AUTOSAR XML (schema 4-2-2)
package /AUTOSAR_Dcm/SwComponentTypes
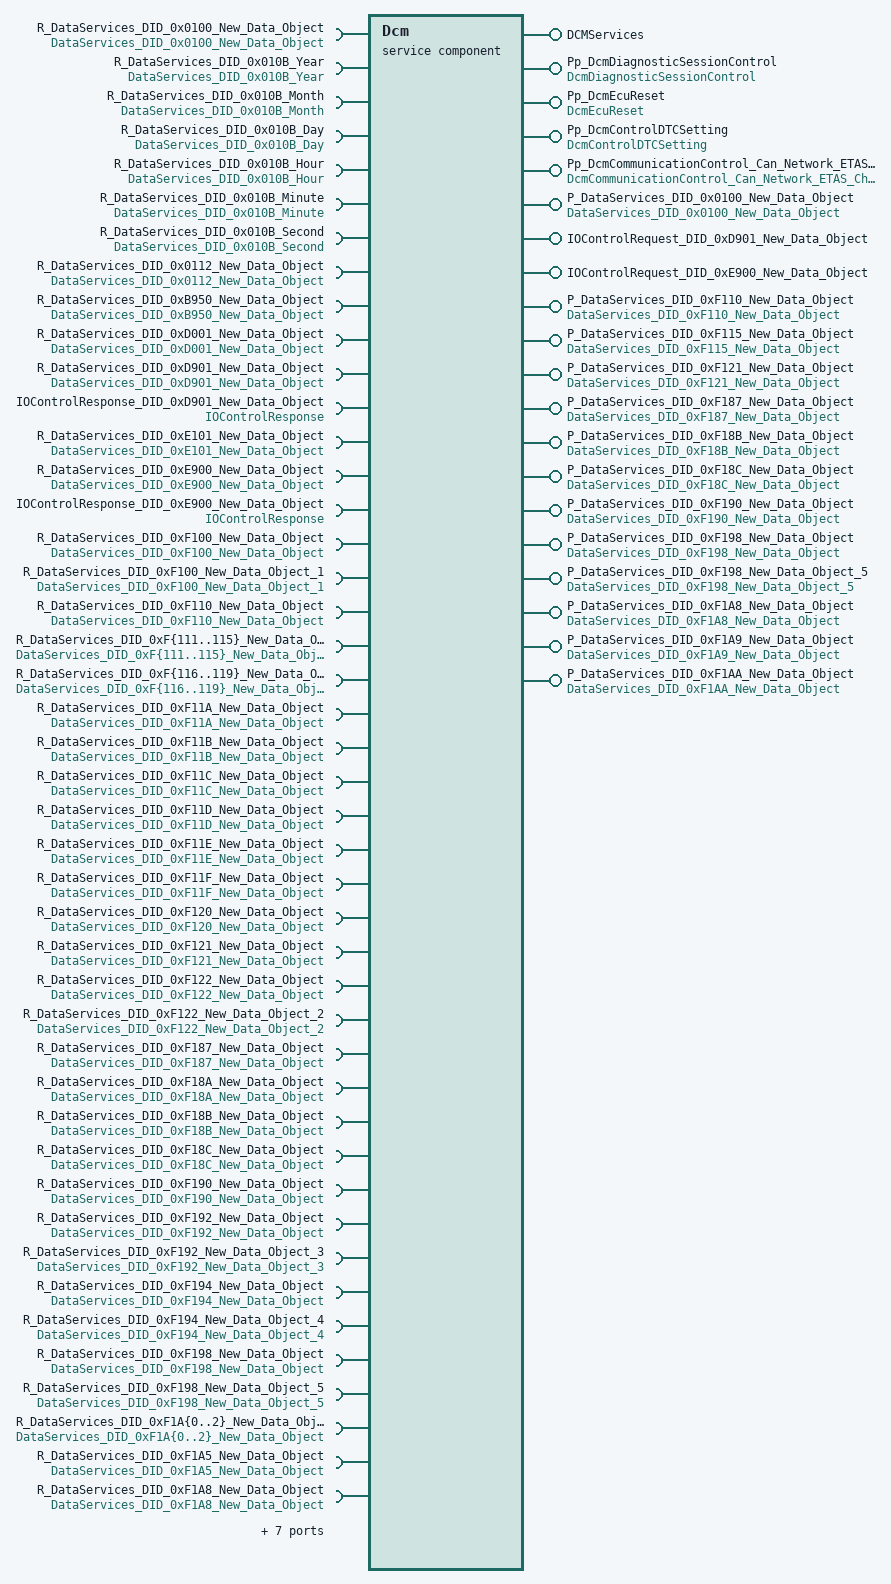
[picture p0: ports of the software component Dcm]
  service sw component type Dcm
    5 x provide port:
      DCMServices: provided-interface=DCMServices
        provided-com-specs:
          operation=GetActiveProtocol, queue-length=1
          operation=SetActiveDiagnostic, queue-length=1
          operation=GetSesCtrlType, queue-length=1
          operation=GetSecurityLevel, queue-length=1
          operation=ResetToDefaultSession, queue-length=1
      Pp_DcmDiagnosticSessionControl: mode-switch-sender-com-spec{mode-group=MDGP_DcmDiagnosticSessionControl, queue-length=1}, provided-interface=DcmDiagnosticSessionControl
      Pp_DcmEcuReset: mode-switch-sender-com-spec{mode-group=MDGP_DcmEcuReset, queue-length=1}, provided-interface=DcmEcuReset
      Pp_DcmControlDTCSetting: mode-switch-sender-com-spec{mode-group=MDGP_DcmControlDTCSetting, queue-length=1}, provided-interface=DcmControlDTCSetting
      Pp_DcmCommunicationControl_Can_Network_ETAS_Channel_Can_Network_ETAS: mode-switch-sender-com-spec{mode-group=MDGP_DcmCommunicationControl_Can_Network_ETAS_Channel_Can_Network_ETAS, queue-length=1}, provided-interface=DcmCommunicationControl_Can_Network_ETAS_Channel_Can_Network_ETAS
    require port R_DataServices_DID_0x0100_New_Data_Object: required-interface=DataServices_DID_0x0100_New_Data_Object
    provide port P_DataServices_DID_0x0100_New_Data_Object: provided-interface=DataServices_DID_0x0100_New_Data_Object
    10 x require port:
      R_DataServices_DID_0x010B_Year: required-interface=DataServices_DID_0x010B_Year
      R_DataServices_DID_0x010B_Month: required-interface=DataServices_DID_0x010B_Month
      R_DataServices_DID_0x010B_Day: required-interface=DataServices_DID_0x010B_Day
      R_DataServices_DID_0x010B_Hour: required-interface=DataServices_DID_0x010B_Hour
      R_DataServices_DID_0x010B_Minute: required-interface=DataServices_DID_0x010B_Minute
      R_DataServices_DID_0x010B_Second: required-interface=DataServices_DID_0x010B_Second
      R_DataServices_DID_0x0112_New_Data_Object: required-interface=DataServices_DID_0x0112_New_Data_Object
      R_DataServices_DID_0xB950_New_Data_Object: required-interface=DataServices_DID_0xB950_New_Data_Object
      R_DataServices_DID_0xD001_New_Data_Object: required-interface=DataServices_DID_0xD001_New_Data_Object
      R_DataServices_DID_0xD901_New_Data_Object: required-interface=DataServices_DID_0xD901_New_Data_Object
    provide port IOControlRequest_DID_0xD901_New_Data_Object: provided-interface=IOControlRequest_DID_0xD901_New_Data_Object
    require port IOControlResponse_DID_0xD901_New_Data_Object: required-interface=IOControlResponse
    require port R_DataServices_DID_0xE101_New_Data_Object: required-interface=DataServices_DID_0xE101_New_Data_Object
    require port R_DataServices_DID_0xE900_New_Data_Object: required-interface=DataServices_DID_0xE900_New_Data_Object
    provide port IOControlRequest_DID_0xE900_New_Data_Object: provided-interface=IOControlRequest_DID_0xE900_New_Data_Object
    4 x require port:
      IOControlResponse_DID_0xE900_New_Data_Object: required-interface=IOControlResponse
      R_DataServices_DID_0xF100_New_Data_Object: required-interface=DataServices_DID_0xF100_New_Data_Object
      R_DataServices_DID_0xF100_New_Data_Object_1: required-interface=DataServices_DID_0xF100_New_Data_Object_1
      R_DataServices_DID_0xF110_New_Data_Object: required-interface=DataServices_DID_0xF110_New_Data_Object
    provide port P_DataServices_DID_0xF110_New_Data_Object: provided-interface=DataServices_DID_0xF110_New_Data_Object
    5 x require port:
      R_DataServices_DID_0xF{111..115}_New_Data_Object: required-interface=DataServices_DID_0xF{111..115}_New_Data_Object
    provide port P_DataServices_DID_0xF115_New_Data_Object: provided-interface=DataServices_DID_0xF115_New_Data_Object
    12 x require port:
      R_DataServices_DID_0xF{116..119}_New_Data_Object: required-interface=DataServices_DID_0xF{116..119}_New_Data_Object
      R_DataServices_DID_0xF11A_New_Data_Object: required-interface=DataServices_DID_0xF11A_New_Data_Object
      R_DataServices_DID_0xF11B_New_Data_Object: required-interface=DataServices_DID_0xF11B_New_Data_Object
      R_DataServices_DID_0xF11C_New_Data_Object: required-interface=DataServices_DID_0xF11C_New_Data_Object
      R_DataServices_DID_0xF11D_New_Data_Object: required-interface=DataServices_DID_0xF11D_New_Data_Object
      R_DataServices_DID_0xF11E_New_Data_Object: required-interface=DataServices_DID_0xF11E_New_Data_Object
      R_DataServices_DID_0xF11F_New_Data_Object: required-interface=DataServices_DID_0xF11F_New_Data_Object
      R_DataServices_DID_0xF120_New_Data_Object: required-interface=DataServices_DID_0xF120_New_Data_Object
      R_DataServices_DID_0xF121_New_Data_Object: required-interface=DataServices_DID_0xF121_New_Data_Object
    provide port P_DataServices_DID_0xF121_New_Data_Object: provided-interface=DataServices_DID_0xF121_New_Data_Object
    require port R_DataServices_DID_0xF122_New_Data_Object: required-interface=DataServices_DID_0xF122_New_Data_Object
    require port R_DataServices_DID_0xF122_New_Data_Object_2: required-interface=DataServices_DID_0xF122_New_Data_Object_2
    require port R_DataServices_DID_0xF187_New_Data_Object: required-interface=DataServices_DID_0xF187_New_Data_Object
    provide port P_DataServices_DID_0xF187_New_Data_Object: provided-interface=DataServices_DID_0xF187_New_Data_Object
    require port R_DataServices_DID_0xF18A_New_Data_Object: required-interface=DataServices_DID_0xF18A_New_Data_Object
    require port R_DataServices_DID_0xF18B_New_Data_Object: required-interface=DataServices_DID_0xF18B_New_Data_Object
    provide port P_DataServices_DID_0xF18B_New_Data_Object: provided-interface=DataServices_DID_0xF18B_New_Data_Object
    require port R_DataServices_DID_0xF18C_New_Data_Object: required-interface=DataServices_DID_0xF18C_New_Data_Object
    provide port P_DataServices_DID_0xF18C_New_Data_Object: provided-interface=DataServices_DID_0xF18C_New_Data_Object
    require port R_DataServices_DID_0xF190_New_Data_Object: required-interface=DataServices_DID_0xF190_New_Data_Object
    provide port P_DataServices_DID_0xF190_New_Data_Object: provided-interface=DataServices_DID_0xF190_New_Data_Object
    5 x require port:
      R_DataServices_DID_0xF192_New_Data_Object: required-interface=DataServices_DID_0xF192_New_Data_Object
      R_DataServices_DID_0xF192_New_Data_Object_3: required-interface=DataServices_DID_0xF192_New_Data_Object_3
      R_DataServices_DID_0xF194_New_Data_Object: required-interface=DataServices_DID_0xF194_New_Data_Object
      R_DataServices_DID_0xF194_New_Data_Object_4: required-interface=DataServices_DID_0xF194_New_Data_Object_4
      R_DataServices_DID_0xF198_New_Data_Object: required-interface=DataServices_DID_0xF198_New_Data_Object
    provide port P_DataServices_DID_0xF198_New_Data_Object: provided-interface=DataServices_DID_0xF198_New_Data_Object
    require port R_DataServices_DID_0xF198_New_Data_Object_5: required-interface=DataServices_DID_0xF198_New_Data_Object_5
    provide port P_DataServices_DID_0xF198_New_Data_Object_5: provided-interface=DataServices_DID_0xF198_New_Data_Object_5
    5 x require port:
      R_DataServices_DID_0xF1A{0..2}_New_Data_Object: required-interface=DataServices_DID_0xF1A{0..2}_New_Data_Object
      R_DataServices_DID_0xF1A5_New_Data_Object: required-interface=DataServices_DID_0xF1A5_New_Data_Object
      R_DataServices_DID_0xF1A8_New_Data_Object: required-interface=DataServices_DID_0xF1A8_New_Data_Object
    provide port P_DataServices_DID_0xF1A8_New_Data_Object: provided-interface=DataServices_DID_0xF1A8_New_Data_Object
    require port R_DataServices_DID_0xF1A9_New_Data_Object: required-interface=DataServices_DID_0xF1A9_New_Data_Object
    provide port P_DataServices_DID_0xF1A9_New_Data_Object: provided-interface=DataServices_DID_0xF1A9_New_Data_Object
    require port R_DataServices_DID_0xF1AA_New_Data_Object: required-interface=DataServices_DID_0xF1AA_New_Data_Object
    provide port P_DataServices_DID_0xF1AA_New_Data_Object: provided-interface=DataServices_DID_0xF1AA_New_Data_Object
    5 x require port:
      SecurityAccess_UnlockedL1: required-interface=SecurityAccess_UnlockedL1
      SecurityAccess_Unlocked_L3: required-interface=SecurityAccess_Unlocked_L3
      RoutineServices_Routine_Control_203: required-interface=RoutineServices_Routine_Control_203
      RoutineServices_X_Routine_Control_ABFE: required-interface=RoutineServices_X_Routine_Control_ABFE
      RoutineServices_Routine_Control_ABFF: required-interface=RoutineServices_Routine_Control_ABFF
    behavior IntBeh_Dcm: data-type-mapping=[DTS_DcmDiagnosticSessionControl, DTS_DcmEcuReset, DTS_DcmControlDTCSetting, DTS_DcmCommunicationControl_Can_Network_ETAS_Channel_Can_Network_ETAS, DTS_DcmDspDid_FOR_DEM_SR_FF_267_Year, DTS_DcmDspDid_FOR_DEM_SR_FF_267_Month, DTS_DcmDspDid_FOR_DEM_SR_FF_267_Day, DTS_DcmDspDid_FOR_DEM_SR_FF_267_Hour, DTS_DcmDspDid_FOR_DEM_SR_FF_267_Minute, DTS_DcmDspDid_FOR_DEM_SR_FF_267_Second, DTS_DcmDspDid_FOR_DEM_SR_FF_274_New_Data_Object, DTS_DcmDspDid_FOR_DEM_SR_FF_53249_New_Data_Object, DTS_DcmDspDid_FOR_DEM_SR_FF_55553_New_Data_Object, DTS_DcmDspDid_FOR_DEM_SR_FF_57601_New_Data_Object, DTS_DcmDspDid_FOR_DEM_SR_EDR_Record_ExtendedDataRecord0x01_Fault_occurrence_counter, DTS_DcmDspDid_FOR_DEM_SR_EDR_Record_ExtendedDataRecord0x01_Fault_pending_counter, DTS_DcmDspDid_FOR_DEM_SR_EDR_Record_ExtendedDataRecord0x01_Aged_counter, DTS_DcmDspDid_FOR_DEM_SR_EDR_Record_ExtendedDataRecord0x01_Ageing_counter, DTS_DcmDspDid_DID_0x0100_New_Data_Object, DTS_DcmDspDid_DID_0x010B_Year, DTS_DcmDspDid_DID_0x010B_Month, DTS_DcmDspDid_DID_0x010B_Day, DTS_DcmDspDid_DID_0x010B_Hour, DTS_DcmDspDid_DID_0x010B_Minute, DTS_DcmDspDid_DID_0x010B_Second, DTS_DcmDspDid_DID_0x0112_New_Data_Object, DTS_DcmDspDid_DID_0xB950_New_Data_Object, DTS_DcmDspDid_DID_0xD001_New_Data_Object, DTS_DcmDspDid_DID_0xD901_New_Data_Object, DTS_DcmDspDid_DID_0xE101_New_Data_Object, DTS_DcmDspDid_DID_0xE900_New_Data_Object, DTS_DcmDspDid_DID_0xF100_New_Data_Object, DTS_DcmDspDid_DID_0xF100_New_Data_Object_1, DTS_DcmDspDid_DID_0xF110_New_Data_Object, DTS_DcmDspDid_DID_0xF111_New_Data_Object, DTS_DcmDspDid_DID_0xF112_New_Data_Object, DTS_DcmDspDid_DID_0xF113_New_Data_Object, DTS_DcmDspDid_DID_0xF114_New_Data_Object, DTS_DcmDspDid_DID_0xF115_New_Data_Object, DTS_DcmDspDid_DID_0xF116_New_Data_Object, DTS_DcmDspDid_DID_0xF117_New_Data_Object, DTS_DcmDspDid_DID_0xF118_New_Data_Object, DTS_DcmDspDid_DID_0xF119_New_Data_Object, DTS_DcmDspDid_DID_0xF11A_New_Data_Object, DTS_DcmDspDid_DID_0xF11B_New_Data_Object, DTS_DcmDspDid_DID_0xF11C_New_Data_Object, DTS_DcmDspDid_DID_0xF11D_New_Data_Object, DTS_DcmDspDid_DID_0xF11E_New_Data_Object, DTS_DcmDspDid_DID_0xF11F_New_Data_Object, DTS_DcmDspDid_DID_0xF120_New_Data_Object, DTS_DcmDspDid_DID_0xF121_New_Data_Object, DTS_DcmDspDid_DID_0xF122_New_Data_Object, DTS_DcmDspDid_DID_0xF122_New_Data_Object_2, DTS_DcmDspDid_DID_0xF187_New_Data_Object, DTS_DcmDspDid_DID_0xF18A_New_Data_Object, DTS_DcmDspDid_DID_0xF18B_New_Data_Object, DTS_DcmDspDid_DID_0xF18C_New_Data_Object, DTS_DcmDspDid_DID_0xF190_New_Data_Object, DTS_DcmDspDid_DID_0xF192_New_Data_Object, DTS_DcmDspDid_DID_0xF192_New_Data_Object_3, DTS_DcmDspDid_DID_0xF194_New_Data_Object, DTS_DcmDspDid_DID_0xF194_New_Data_Object_4, DTS_DcmDspDid_DID_0xF198_New_Data_Object, DTS_DcmDspDid_DID_0xF198_New_Data_Object_5, DTS_DcmDspDid_DID_0xF1A0_New_Data_Object, DTS_DcmDspDid_DID_0xF1A1_New_Data_Object, DTS_DcmDspDid_DID_0xF1A2_New_Data_Object, DTS_DcmDspDid_DID_0xF1A5_New_Data_Object, DTS_DcmDspDid_DID_0xF1A8_New_Data_Object, DTS_DcmDspDid_DID_0xF1A9_New_Data_Object, DTS_DcmDspDid_DID_0xF1AA_New_Data_Object, DTS_DcmDspRoutine_Routine_Control_203_StartOut_DcmDspStartRoutineOutSignal_0, DTS_DcmDspRoutine_Routine_Control_ABFF_RequestResultsOut_DcmDspRequestRoutineResultsOutSignal_0], included-data-type-set=data-type=[Dcm_SecLevelType, Dcm_SesCtrlType, Dcm_ProtocolType, Dcm_NegativeResponseCodeType, Dcm_ConfirmationStatusType, Dcm_OpStatusType, Dcm_DidSupportedType]
      5 x operation invoked event:
        OpInvEvent_DCMServices_GAP: start-on-event=Dcm_GetActiveProtocol, operation=DCMServices.GetActiveProtocol
        OpInvEvent_DCMServices_SAD: start-on-event=Dcm_SetActiveDiagnostic, operation=DCMServices.SetActiveDiagnostic
        OpInvEvent_DCMServices_GSCT: start-on-event=Dcm_GetSesCtrlType, operation=DCMServices.GetSesCtrlType
        OpInvEvent_DCMServices_GSL: start-on-event=Dcm_GetSecurityLevel, operation=DCMServices.GetSecurityLevel
        OpInvEvent_DCMServices_RD: start-on-event=Dcm_ResetToDefaultSession, operation=DCMServices.ResetToDefaultSession
      port-api-options:
        enable-take-address=true, indirect-api=false, port=SecurityAccess_UnlockedL1
        enable-take-address=true, indirect-api=false, port=SecurityAccess_Unlocked_L3
        enable-take-address=true, indirect-api=false, port=RoutineServices_Routine_Control_203
        enable-take-address=true, indirect-api=false, port=RoutineServices_X_Routine_Control_ABFE
        enable-take-address=true, indirect-api=false, port=RoutineServices_Routine_Control_ABFF
      6 x runnable:
        Dcm_MainFunction
          data-receive-point-by-arguments:
            55 x access:
              DID_0x0100_New_Data_Object_Read: accessed-variable=R_DataServices_DID_0x0100_New_Data_Object.Data
              DID_0x010B_Year_Read: accessed-variable=R_DataServices_DID_0x010B_Year.Data
              DID_0x010B_Month_Read: accessed-variable=R_DataServices_DID_0x010B_Month.Data
              DID_0x010B_Day_Read: accessed-variable=R_DataServices_DID_0x010B_Day.Data
              DID_0x010B_Hour_Read: accessed-variable=R_DataServices_DID_0x010B_Hour.Data
              DID_0x010B_Minute_Read: accessed-variable=R_DataServices_DID_0x010B_Minute.Data
              DID_0x010B_Second_Read: accessed-variable=R_DataServices_DID_0x010B_Second.Data
              DID_0x0112_New_Data_Object_Read: accessed-variable=R_DataServices_DID_0x0112_New_Data_Object.Data
              DID_0xB950_New_Data_Object_Read: accessed-variable=R_DataServices_DID_0xB950_New_Data_Object.Data
              DID_0xD001_New_Data_Object_Read: accessed-variable=R_DataServices_DID_0xD001_New_Data_Object.Data
              DID_0xD901_New_Data_Object_Read: accessed-variable=R_DataServices_DID_0xD901_New_Data_Object.Data
              IOControlResponse_DID_0xD901_New_Data_Object: accessed-variable=IOControlResponse_DID_0xD901_New_Data_Object.IOOperationResponse
              DID_0xE101_New_Data_Object_Read: accessed-variable=R_DataServices_DID_0xE101_New_Data_Object.Data
              DID_0xE900_New_Data_Object_Read: accessed-variable=R_DataServices_DID_0xE900_New_Data_Object.Data
              IOControlResponse_DID_0xE900_New_Data_Object: accessed-variable=IOControlResponse_DID_0xE900_New_Data_Object.IOOperationResponse
              DID_0xF100_New_Data_Object_Read: accessed-variable=R_DataServices_DID_0xF100_New_Data_Object.Data
              DID_0xF100_New_Data_Object_1_Read: accessed-variable=R_DataServices_DID_0xF100_New_Data_Object_1.Data
              DID_0xF{110..119}_New_Data_Object_Read: accessed-variable=R_DataServices_DID_0xF{110..119}_New_Data_Object.Data
              DID_0xF11A_New_Data_Object_Read: accessed-variable=R_DataServices_DID_0xF11A_New_Data_Object.Data
              DID_0xF11B_New_Data_Object_Read: accessed-variable=R_DataServices_DID_0xF11B_New_Data_Object.Data
              DID_0xF11C_New_Data_Object_Read: accessed-variable=R_DataServices_DID_0xF11C_New_Data_Object.Data
              DID_0xF11D_New_Data_Object_Read: accessed-variable=R_DataServices_DID_0xF11D_New_Data_Object.Data
              DID_0xF11E_New_Data_Object_Read: accessed-variable=R_DataServices_DID_0xF11E_New_Data_Object.Data
              DID_0xF11F_New_Data_Object_Read: accessed-variable=R_DataServices_DID_0xF11F_New_Data_Object.Data
              DID_0xF{120..122}_New_Data_Object_Read: accessed-variable=R_DataServices_DID_0xF{120..122}_New_Data_Object.Data
              DID_0xF122_New_Data_Object_2_Read: accessed-variable=R_DataServices_DID_0xF122_New_Data_Object_2.Data
              DID_0xF187_New_Data_Object_Read: accessed-variable=R_DataServices_DID_0xF187_New_Data_Object.Data
              DID_0xF18A_New_Data_Object_Read: accessed-variable=R_DataServices_DID_0xF18A_New_Data_Object.Data
              DID_0xF18B_New_Data_Object_Read: accessed-variable=R_DataServices_DID_0xF18B_New_Data_Object.Data
              DID_0xF18C_New_Data_Object_Read: accessed-variable=R_DataServices_DID_0xF18C_New_Data_Object.Data
              DID_0xF190_New_Data_Object_Read: accessed-variable=R_DataServices_DID_0xF190_New_Data_Object.Data
              DID_0xF192_New_Data_Object_Read: accessed-variable=R_DataServices_DID_0xF192_New_Data_Object.Data
              DID_0xF192_New_Data_Object_3_Read: accessed-variable=R_DataServices_DID_0xF192_New_Data_Object_3.Data
              DID_0xF194_New_Data_Object_Read: accessed-variable=R_DataServices_DID_0xF194_New_Data_Object.Data
              DID_0xF194_New_Data_Object_4_Read: accessed-variable=R_DataServices_DID_0xF194_New_Data_Object_4.Data
              DID_0xF198_New_Data_Object_Read: accessed-variable=R_DataServices_DID_0xF198_New_Data_Object.Data
              DID_0xF198_New_Data_Object_5_Read: accessed-variable=R_DataServices_DID_0xF198_New_Data_Object_5.Data
              DID_0xF1A{0..2}_New_Data_Object_Read: accessed-variable=R_DataServices_DID_0xF1A{0..2}_New_Data_Object.Data
              DID_0xF1A5_New_Data_Object_Read: accessed-variable=R_DataServices_DID_0xF1A5_New_Data_Object.Data
              DID_0xF1A8_New_Data_Object_Read: accessed-variable=R_DataServices_DID_0xF1A8_New_Data_Object.Data
              DID_0xF1A9_New_Data_Object_Read: accessed-variable=R_DataServices_DID_0xF1A9_New_Data_Object.Data
              DID_0xF1AA_New_Data_Object_Read: accessed-variable=R_DataServices_DID_0xF1AA_New_Data_Object.Data
          data-send-points:
            15 x access:
              DID_0x0100_New_Data_Object_Write: accessed-variable=P_DataServices_DID_0x0100_New_Data_Object.Data
              IOControlRequest_DID_0xD901_New_Data_Object: accessed-variable=IOControlRequest_DID_0xD901_New_Data_Object.IOControlRequest_DID_0xD901_New_Data_Object
              IOControlRequest_DID_0xE900_New_Data_Object: accessed-variable=IOControlRequest_DID_0xE900_New_Data_Object.IOControlRequest_DID_0xE900_New_Data_Object
              DID_0xF110_New_Data_Object_Write: accessed-variable=P_DataServices_DID_0xF110_New_Data_Object.Data
              DID_0xF115_New_Data_Object_Write: accessed-variable=P_DataServices_DID_0xF115_New_Data_Object.Data
              DID_0xF121_New_Data_Object_Write: accessed-variable=P_DataServices_DID_0xF121_New_Data_Object.Data
              DID_0xF187_New_Data_Object_Write: accessed-variable=P_DataServices_DID_0xF187_New_Data_Object.Data
              DID_0xF18B_New_Data_Object_Write: accessed-variable=P_DataServices_DID_0xF18B_New_Data_Object.Data
              DID_0xF18C_New_Data_Object_Write: accessed-variable=P_DataServices_DID_0xF18C_New_Data_Object.Data
              DID_0xF190_New_Data_Object_Write: accessed-variable=P_DataServices_DID_0xF190_New_Data_Object.Data
              DID_0xF198_New_Data_Object_Write: accessed-variable=P_DataServices_DID_0xF198_New_Data_Object.Data
              DID_0xF198_New_Data_Object_5_Write: accessed-variable=P_DataServices_DID_0xF198_New_Data_Object_5.Data
              DID_0xF1A8_New_Data_Object_Write: accessed-variable=P_DataServices_DID_0xF1A8_New_Data_Object.Data
              DID_0xF1A9_New_Data_Object_Write: accessed-variable=P_DataServices_DID_0xF1A9_New_Data_Object.Data
              DID_0xF1AA_New_Data_Object_Write: accessed-variable=P_DataServices_DID_0xF1AA_New_Data_Object.Data
          4 x mode switch point:
            ModeSwitchPoint_0: mode-group=Pp_DcmDiagnosticSessionControl.MDGP_DcmDiagnosticSessionControl
            ModeSwitchPoint_1: mode-group=Pp_DcmEcuReset.MDGP_DcmEcuReset
            ModeSwitchPoint_3: mode-group=Pp_DcmControlDTCSetting.MDGP_DcmControlDTCSetting
            ModeSwitchPoint_Can_Network_ETAS_Channel_Can_Network_ETAS: mode-group=Pp_DcmCommunicationControl_Can_Network_ETAS_Channel_Can_Network_ETAS.MDGP_DcmCommunicationControl_Can_Network_ETAS_Channel_Can_Network_ETAS
          8 x sync call, all with timeout=0.0:
            SSC_SeCa_UnlockedL1_GS: operation=SecurityAccess_UnlockedL1.GetSeed
            SSC_SeCa_UnlockedL1_CK: operation=SecurityAccess_UnlockedL1.CompareKey
            SSC_SeCa_Unlocked_L3_GS: operation=SecurityAccess_Unlocked_L3.GetSeed
            SSC_SeCa_Unlocked_L3_CK: operation=SecurityAccess_Unlocked_L3.CompareKey
            SSC_Rout_Routine_Control_203_Start: operation=RoutineServices_Routine_Control_203.Start
            SSC_Rout_X_Routine_Control_ABFE_Start: operation=RoutineServices_X_Routine_Control_ABFE.Start
            SSC_Rout_Routine_Control_ABFF_Start: operation=RoutineServices_Routine_Control_ABFF.Start
            SSC_Rout_Routine_Control_ABFF_ReqRes: operation=RoutineServices_Routine_Control_ABFF.RequestResults
        Dcm_GetActiveProtocol: can-be-invoked-concurrently=true
        Dcm_SetActiveDiagnostic: can-be-invoked-concurrently=true
        Dcm_GetSesCtrlType: can-be-invoked-concurrently=true
        Dcm_GetSecurityLevel: can-be-invoked-concurrently=true
        Dcm_ResetToDefaultSession: can-be-invoked-concurrently=true
package /AUTOSAR_Dcm/SwcImplementations
  swc implementation Impl_Dcm: programming-language=C, sw-version=42.9.0.0, swc-bsw-mapping=SwcBswMappings, vendor-id=6, behavior=IntBeh_Dcm
    code-descriptors:
      code CodeDescr_Dcm: artifact-descriptors=autosar-engineering-object={short-label=Code_0, category=SWSRC}
package /AUTOSAR_Dcm/CompuMethods
  compu method Dcm_RidSupportedType_Values: 0=DCM_RID_SUPPORTED_IN_RANGE, 1=DCM_RID_NOT_SUPPORTED
package /AUTOSAR_Dcm/ImplementationDataTypes
  76 x impl type:
    Dcm_SesCtrlType: compu {1=DCM_DEFAULT_SESSION, 2=DCM_PROGRAMMING_SESSION, 3=DCM_EXTENDED_DIAGNOSTIC_SESSION, 4=DCM_SAFETY_SYSTEM_DIAGNOSTIC_SESSION}, implementation-data-type=uint8
    Dcm_NegativeResponseCodeType: compu {0=DCM_POS_RESP, 17=DCM_E_SERVICENOTSUPPORTED, 18=DCM_E_SUBFUNCTIONNOTSUPPORTED, 19=DCM_E_INCORRECTMESSAGELENGTHORINVALIDFORMAT, 20=DCM_E_RESPONSETOOLONG, 53=DCM_E_INVALIDKEY, 54=DCM_E_EXCEEDNUMBEROFATTEMPTS, 55=DCM_E_REQUIREDTIMEDELAYNOTEXPIRED, 112=DCM_E_UPLOADDOWNLOADNOTACCEPTED, 113=DCM_E_TRANSFERDATASUSPENDED, 115=DCM_E_WRONGBLOCKSEQUENCECOUNTER, 127=DCM_E_SERVICENOTSUPPORTEDINACTIVESESSION, 140=DCM_E_TRANSMISSIONRANGENOTINNEUTRAL, 34=DCM_E_CONDITIONSNOTCORRECT, 16=DCM_E_GENERALREJECT, 33=DCM_E_BUSYREPEATREQUEST, 36=DCM_E_REQUESTSEQUENCEERROR, 37=DCM_E_NORESPONSEFROMSUBNETCOMPONENT, 38=DCM_E_FAILUREPREVENTSEXECUTIONOFREQUESTEDACTION, 49=DCM_E_REQUESTOUTOFRANGE, 51=DCM_E_SECURITYACCESSDENIED, 114=DCM_E_GENERALPROGRAMMINGFAILURE, 126=DCM_E_SUBFUNCTIONNOTSUPPORTEDINACTIVESESSION, 129=DCM_E_RPMTOOHIGH, 130=DCM_E_RPMTOOLOW, 131=DCM_E_ENGINEISRUNNING, 132=DCM_E_ENGINEISNOTRUNNING, 133=DCM_E_ENGINERUNTIMETOOLOW, 134=DCM_E_TEMPERATURETOOHIGH, 135=DCM_E_TEMPERATURETOOLOW, 136=DCM_E_VEHICLESPEEDTOOHIGH, 137=DCM_E_VEHICLESPEEDTOOLOW, 138=DCM_E_THROTTLE_PEDALTOOHIGH, 139=DCM_E_THROTTLE_PEDALTOOLOW, 141=DCM_E_TRANSMISSIONRANGENOTINGEAR, 146=DCM_E_VOLTAGETOOHIGH, 143=DCM_E_BRAKESWITCH_NOTCLOSED, 144=DCM_E_SHIFTERLEVERNOTINPARK, 145=DCM_E_TORQUECONVERTERCLUTCHLOCKED, 147=DCM_E_VOLTAGETOOLOW, 0=DCM_E_POSITIVERESPONSE, 120=DCM_E_REQUESTCORRECTLYRECEIVEDRESPONSEPENDING, 148=DCM_E_RESOURCETEMPORARILYNOTAVAILABLE, 240..249=DCM_E_VMSCNC_0..DCM_E_VMSCNC_9, 250=DCM_E_VMSCNC_A, 251=DCM_E_VMSCNC_B, 252=DCM_E_VMSCNC_C, 253=DCM_E_VMSCNC_D, 254=DCM_E_VMSCNC_E}, implementation-data-type=uint8
    Dcm_InputOutputControlParameterType: compu {255=DCM_IDLE, 3=DCM_SHORT_TERM_ADJUSTMENT, 2=DCM_FREEZE_CURRENT_STATE, 1=DCM_RESET_TO_DEFAULT, 0=DCM_RETURN_CONTROL_TO_ECU}, implementation-data-type=uint8
    Dcm_IOOperationResponseType: compu {255=DCM_IDLE, 0=DCM_POSITIVE_RESPONSE, 16=DCM_GENERAL_REJECT, 33=DCM_BUSY_REPEAT_REQUEST, 34=DCM_CONDITIONS_NOT_CORRECT, 38=DCM_FAILURE_PREVENTS_EXECUTION, 49=DCM_REQUEST_OUT_OF_RANGE, 120=DCM_RESPONSE_PENDING}, implementation-data-type=uint8
    Dcm_IOControlResponseType: category=STRUCTURE
      element IOOperationResponse: implementation-data-type=Dcm_IOOperationResponseType
    Dcm_ControlMask_32Type: implementation-data-type=uint32
    Dcm_IOOperationRequest_DID_0xD901_New_Data_ObjectType: category=STRUCTURE
      element inputOutputControlParameter: implementation-data-type=Dcm_InputOutputControlParameterType
      element controlEnableMask: implementation-data-type=Dcm_ControlMask_32Type
    Dcm_IOControlRequest_DID_0xD901_New_Data_ObjectType: category=STRUCTURE
      element undercontrol: implementation-data-type=Dcm_ControlMask_32Type
      element IOOperationRequest: implementation-data-type=Dcm_IOOperationRequest_DID_0xD901_New_Data_ObjectType
      element controlState: implementation-data-type=Dcm_DataArrayTypeUint8_DID_0xD901_New_Data_ObjectType
    Dcm_IOOperationRequest_DID_0xE900_New_Data_ObjectType: category=STRUCTURE
      element inputOutputControlParameter: implementation-data-type=Dcm_InputOutputControlParameterType
      element controlEnableMask: implementation-data-type=Dcm_ControlMask_32Type
    Dcm_IOControlRequest_DID_0xE900_New_Data_ObjectType: category=STRUCTURE
      element undercontrol: implementation-data-type=Dcm_ControlMask_32Type
      element IOOperationRequest: implementation-data-type=Dcm_IOOperationRequest_DID_0xE900_New_Data_ObjectType
      element controlState: implementation-data-type=Dcm_DataArrayTypeUint8_DID_0xE900_New_Data_ObjectType
    Dcm_DataArrayTypeUint8_DID_0x0100_New_Data_ObjectType: category=ARRAY
      element DataArray: array-size=16, array-size-semantics=FIXED-SIZE, implementation-data-type=uint8
    Dcm_DataArrayTypeUint8_DID_0x010B_YearType: implementation-data-type=uint8
    Dcm_DataArrayTypeUint8_DID_0x010B_MonthType: implementation-data-type=uint8
    Dcm_DataArrayTypeUint8_DID_0x010B_DayType: implementation-data-type=uint8
    Dcm_DataArrayTypeUint8_DID_0x010B_HourType: implementation-data-type=uint8
    Dcm_DataArrayTypeUint8_DID_0x010B_MinuteType: implementation-data-type=uint8
    Dcm_DataArrayTypeUint8_DID_0x010B_SecondType: implementation-data-type=uint8
    Dcm_DataArrayTypeUint8_DID_0x0112_New_Data_ObjectType: implementation-data-type=uint8
    Dcm_DataArrayTypeUint8_DID_0xB950_New_Data_ObjectType: category=ARRAY
      element DataArray: array-size=8, array-size-semantics=FIXED-SIZE, implementation-data-type=uint8
    Dcm_DataArrayTypeUint8_DID_0xD001_New_Data_ObjectType: implementation-data-type=uint8
    Dcm_DataArrayTypeUint8_DID_0xD901_New_Data_ObjectType: implementation-data-type=uint8
    Dcm_DataArrayTypeUint8_DID_0xE101_New_Data_ObjectType: category=ARRAY
      element DataArray: array-size=3, array-size-semantics=FIXED-SIZE, implementation-data-type=uint8
    Dcm_DataArrayTypeUint8_DID_0xE900_New_Data_ObjectType: implementation-data-type=uint8
    Dcm_DataArrayTypeUint8_DID_0xF100_New_Data_ObjectType: category=ARRAY
      element DataArray: array-size=5, array-size-semantics=FIXED-SIZE, implementation-data-type=uint8
    Dcm_DataArrayTypeUint8_DID_0xF100_New_Data_Object_1Type: category=ARRAY
      element DataArray: array-size=6, array-size-semantics=FIXED-SIZE, implementation-data-type=uint8
    Dcm_DataArrayTypeUint8_DID_0xF110_New_Data_ObjectType: category=ARRAY
      element DataArray: array-size=16, array-size-semantics=FIXED-SIZE, implementation-data-type=uint8
    Dcm_DataArrayTypeUint8_DID_0xF111_New_Data_ObjectType: category=ARRAY
      element DataArray: array-size=16, array-size-semantics=FIXED-SIZE, implementation-data-type=uint8
    Dcm_DataArrayTypeUint8_DID_0xF112_New_Data_ObjectType: category=ARRAY
      element DataArray: array-size=16, array-size-semantics=FIXED-SIZE, implementation-data-type=uint8
    Dcm_DataArrayTypeUint8_DID_0xF113_New_Data_ObjectType: category=ARRAY
      element DataArray: array-size=16, array-size-semantics=FIXED-SIZE, implementation-data-type=uint8
    Dcm_DataArrayTypeUint8_DID_0xF114_New_Data_ObjectType: category=ARRAY
      element DataArray: array-size=16, array-size-semantics=FIXED-SIZE, implementation-data-type=uint8
    Dcm_DataArrayTypeUint8_DID_0xF115_New_Data_ObjectType: category=ARRAY
      element DataArray: array-size=16, array-size-semantics=FIXED-SIZE, implementation-data-type=uint8
    Dcm_DataArrayTypeUint8_DID_0xF116_New_Data_ObjectType: category=ARRAY
      element DataArray: array-size=16, array-size-semantics=FIXED-SIZE, implementation-data-type=uint8
    Dcm_DataArrayTypeUint8_DID_0xF117_New_Data_ObjectType: category=ARRAY
      element DataArray: array-size=16, array-size-semantics=FIXED-SIZE, implementation-data-type=uint8
    Dcm_DataArrayTypeUint8_DID_0xF118_New_Data_ObjectType: category=ARRAY
      element DataArray: array-size=16, array-size-semantics=FIXED-SIZE, implementation-data-type=uint8
    Dcm_DataArrayTypeUint8_DID_0xF119_New_Data_ObjectType: category=ARRAY
      element DataArray: array-size=16, array-size-semantics=FIXED-SIZE, implementation-data-type=uint8
    Dcm_DataArrayTypeUint8_DID_0xF11A_New_Data_ObjectType: category=ARRAY
      element DataArray: array-size=16, array-size-semantics=FIXED-SIZE, implementation-data-type=uint8
    Dcm_DataArrayTypeUint8_DID_0xF11B_New_Data_ObjectType: category=ARRAY
      element DataArray: array-size=16, array-size-semantics=FIXED-SIZE, implementation-data-type=uint8
    Dcm_DataArrayTypeUint8_DID_0xF11C_New_Data_ObjectType: category=ARRAY
      element DataArray: array-size=16, array-size-semantics=FIXED-SIZE, implementation-data-type=uint8
    Dcm_DataArrayTypeUint8_DID_0xF11D_New_Data_ObjectType: category=ARRAY
      element DataArray: array-size=16, array-size-semantics=FIXED-SIZE, implementation-data-type=uint8
    Dcm_DataArrayTypeUint8_DID_0xF11E_New_Data_ObjectType: category=ARRAY
      element DataArray: array-size=16, array-size-semantics=FIXED-SIZE, implementation-data-type=uint8
    Dcm_DataArrayTypeUint8_DID_0xF11F_New_Data_ObjectType: category=ARRAY
      element DataArray: array-size=16, array-size-semantics=FIXED-SIZE, implementation-data-type=uint8
    Dcm_DataArrayTypeUint8_DID_0xF120_New_Data_ObjectType: category=ARRAY
      element DataArray: array-size=16, array-size-semantics=FIXED-SIZE, implementation-data-type=uint8
    Dcm_DataArrayTypeUint8_DID_0xF121_New_Data_ObjectType: category=ARRAY
      element DataArray: array-size=16, array-size-semantics=FIXED-SIZE, implementation-data-type=uint8
    Dcm_DataArrayTypeUint8_DID_0xF122_New_Data_ObjectType: category=ARRAY
      element DataArray: array-size=5, array-size-semantics=FIXED-SIZE, implementation-data-type=uint8
    Dcm_DataArrayTypeUint8_DID_0xF122_New_Data_Object_2Type: category=ARRAY
      element DataArray: array-size=5, array-size-semantics=FIXED-SIZE, implementation-data-type=uint8
    Dcm_DataArrayTypeUint8_DID_0xF187_New_Data_ObjectType: category=ARRAY
      element DataArray: array-size=5, array-size-semantics=FIXED-SIZE, implementation-data-type=uint8
    Dcm_DataArrayTypeUint8_DID_0xF18A_New_Data_ObjectType: category=ARRAY
      element DataArray: array-size=5, array-size-semantics=FIXED-SIZE, implementation-data-type=uint8
    Dcm_DataArrayTypeUint8_DID_0xF18B_New_Data_ObjectType: category=ARRAY
      element DataArray: array-size=3, array-size-semantics=FIXED-SIZE, implementation-data-type=uint8
    Dcm_DataArrayTypeUint8_DID_0xF18C_New_Data_ObjectType: category=ARRAY
      element DataArray: array-size=16, array-size-semantics=FIXED-SIZE, implementation-data-type=uint8
    Dcm_DataArrayTypeUint8_DID_0xF190_New_Data_ObjectType: category=ARRAY
      element DataArray: array-size=17, array-size-semantics=FIXED-SIZE, implementation-data-type=uint8
    Dcm_DataArrayTypeUint8_DID_0xF192_New_Data_ObjectType: category=ARRAY
      element DataArray: array-size=5, array-size-semantics=FIXED-SIZE, implementation-data-type=uint8
    Dcm_DataArrayTypeUint8_DID_0xF192_New_Data_Object_3Type: category=ARRAY
      element DataArray: array-size=5, array-size-semantics=FIXED-SIZE, implementation-data-type=uint8
    Dcm_DataArrayTypeUint8_DID_0xF194_New_Data_ObjectType: category=ARRAY
      element DataArray: array-size=5, array-size-semantics=FIXED-SIZE, implementation-data-type=uint8
    Dcm_DataArrayTypeUint8_DID_0xF194_New_Data_Object_4Type: category=ARRAY
      element DataArray: array-size=5, array-size-semantics=FIXED-SIZE, implementation-data-type=uint8
    Dcm_DataArrayTypeUint8_DID_0xF198_New_Data_ObjectType: category=ARRAY
      element DataArray: array-size=5, array-size-semantics=FIXED-SIZE, implementation-data-type=uint8
    Dcm_DataArrayTypeUint8_DID_0xF198_New_Data_Object_5Type: category=ARRAY
      element DataArray: array-size=6, array-size-semantics=FIXED-SIZE, implementation-data-type=uint8
    Dcm_DataArrayTypeUint8_DID_0xF1A0_New_Data_ObjectType: category=ARRAY
      element DataArray: array-size=5, array-size-semantics=FIXED-SIZE, implementation-data-type=uint8
    Dcm_DataArrayTypeUint8_DID_0xF1A1_New_Data_ObjectType: category=ARRAY
      element DataArray: array-size=5, array-size-semantics=FIXED-SIZE, implementation-data-type=uint8
    Dcm_DataArrayTypeUint8_DID_0xF1A2_New_Data_ObjectType: category=ARRAY
      element DataArray: array-size=8, array-size-semantics=FIXED-SIZE, implementation-data-type=uint8
    Dcm_DataArrayTypeUint8_DID_0xF1A5_New_Data_ObjectType: category=ARRAY
      element DataArray: array-size=3, array-size-semantics=FIXED-SIZE, implementation-data-type=uint8
    Dcm_DataArrayTypeUint8_DID_0xF1A8_New_Data_ObjectType: category=ARRAY
      element DataArray: array-size=20, array-size-semantics=FIXED-SIZE, implementation-data-type=uint8
    Dcm_DataArrayTypeUint8_DID_0xF1A9_New_Data_ObjectType: category=ARRAY
      element DataArray: array-size=5, array-size-semantics=FIXED-SIZE, implementation-data-type=uint8
    Dcm_DataArrayTypeUint8_DID_0xF1AA_New_Data_ObjectType: category=ARRAY
      element DataArray: array-size=5, array-size-semantics=FIXED-SIZE, implementation-data-type=uint8
    Dcm_ConfirmationStatusType: compu {0=DCM_RES_POS_OK, 1=DCM_RES_POS_NOT_OK, 2=DCM_RES_NEG_OK, 3=DCM_RES_NEG_NOT_OK}, implementation-data-type=uint8
    Dcm_ProtocolType: compu {0=DCM_OBD_ON_CAN, 1=DCM_OBD_ON_FLEXRAY, 2=DCM_OBD_ON_IP, 3=DCM_UDS_ON_CAN, 4=DCM_UDS_ON_FLEXRAY, 5=DCM_UDS_ON_IP, 6=DCM_ROE_ON_CAN, 7=DCM_ROE_ON_FLEXRAY, 8=DCM_ROE_ON_IP, 9=DCM_PERIODICTRANS_ON_CAN, 10=DCM_PERIODICTRANS_ON_FLEXRAY, 11=DCM_PERIODICTRANS_ON_IP, 12=DCM_NO_ACTIVE_PROTOCOL, 144=DCM_ACEA_ON_CAN, 145=DCM_ACEA_ON_FLEXRAY, 128=DCM_KWP_ON_KLINE, 129=DCM_KWP_ON_CAN, 160=DCM_CARB_ON_KLINE, 161=DCM_OBD_ON_KLINE, 240..254=DCM_SUPPLIER_1..DCM_SUPPLIER_15}, implementation-data-type=uint8
    Dcm_SecLevelType: compu {1=DCM_SEC_LEV_L1, 3=Unlocked_L3}, implementation-data-type=uint8
    Dcm_SeedArray_UnlockedL1Type: category=ARRAY
      element DcmDspSecuritySeedSize_UnlockedL1: array-size=4, array-size-semantics=FIXED-SIZE, implementation-data-type=uint8
    Dcm_KeyArray_UnlockedL1Type: category=ARRAY
      element DcmDspSecurityKeySize_1: array-size=4, array-size-semantics=FIXED-SIZE, implementation-data-type=uint8
    Dcm_SeedArray_Unlocked_L3Type: category=ARRAY
      element DcmDspSecuritySeedSize_Unlocked_L3: array-size=4, array-size-semantics=FIXED-SIZE, implementation-data-type=uint8
    Dcm_KeyArray_Unlocked_L3Type: category=ARRAY
      element DcmDspSecurityKeySize_3: array-size=4, array-size-semantics=FIXED-SIZE, implementation-data-type=uint8
    Dcm_StartDataOut_Routine_Control_203_DcmDspStartRoutineOutSignal_0Type: implementation-data-type=Dcm_StartDataOut_Routine_Control_203_DcmDspStartRoutineOutSignal_0PrimitivType
    Dcm_StartDataOut_Routine_Control_203_DcmDspStartRoutineOutSignal_0PrimitivType: implementation-data-type=uint8
    Dcm_RequestDataOut_Routine_Control_ABFF_DcmDspRequestRoutineResultsOutSignal_0Type: implementation-data-type=Dcm_RequestDataOut_Routine_Control_ABFF_DcmDspRequestRoutineResultsOutSignal_0PrimitivType
    Dcm_RequestDataOut_Routine_Control_ABFF_DcmDspRequestRoutineResultsOutSignal_0PrimitivType: implementation-data-type=uint8
    Dcm_OpStatusType: compu {0=DCM_INITIAL, 1=DCM_PENDING, 2=DCM_CANCEL, 3=DCM_FORCE_RCRRP_OK}, implementation-data-type=uint8
    Dcm_DidSupportedType: compu {0=DCM_DID_SUPPORTED, 1=DCM_DID_NOT_SUPPORTED}, implementation-data-type=uint8
package /AUTOSAR_Dcm/DataTypeMappingSets
  73 x data type mapping set:
    DTS_DcmDspRoutine_Routine_Control_203_StartOut_DcmDspStartRoutineOutSignal_0: data-type-map{application-data-type=Dcm_DataType_StartOut_515_Out_New_Data_Object, implementation-data-type=Dcm_StartDataOut_Routine_Control_203_DcmDspStartRoutineOutSignal_0Type}
    DTS_DcmDspRoutine_Routine_Control_ABFF_RequestResultsOut_DcmDspRequestRoutineResultsOutSignal_0: data-type-map{application-data-type=Dcm_DataType_RequestOut_44031_Out_New_Data_Object, implementation-data-type=Dcm_RequestDataOut_Routine_Control_ABFF_DcmDspRequestRoutineResultsOutSignal_0Type}
    DTS_DcmDspDid_FOR_DEM_SR_FF_267_Year: data-type-map{application-data-type=Dem_DataType_Year, implementation-data-type=uint8}
    DTS_DcmDspDid_FOR_DEM_SR_FF_267_Month: data-type-map{application-data-type=Dem_DataType_Month, implementation-data-type=uint8}
    DTS_DcmDspDid_FOR_DEM_SR_FF_267_Day: data-type-map{application-data-type=Dem_DataType_Day, implementation-data-type=uint8}
    DTS_DcmDspDid_FOR_DEM_SR_FF_267_Hour: data-type-map{application-data-type=Dem_DataType_Hour, implementation-data-type=uint8}
    DTS_DcmDspDid_FOR_DEM_SR_FF_267_Minute: data-type-map{application-data-type=Dem_DataType_Minute, implementation-data-type=uint8}
    DTS_DcmDspDid_FOR_DEM_SR_FF_267_Second: data-type-map{application-data-type=Dem_DataType_Second, implementation-data-type=uint8}
    DTS_DcmDspDid_FOR_DEM_SR_FF_274_New_Data_Object: data-type-map{application-data-type=Dem_DataType_New_Data_Object, implementation-data-type=uint8}
    DTS_DcmDspDid_FOR_DEM_SR_FF_53249_New_Data_Object: data-type-map{application-data-type=Dem_DataType_New_Data_Object, implementation-data-type=uint8}
    DTS_DcmDspDid_FOR_DEM_SR_FF_55553_New_Data_Object: data-type-map{application-data-type=Dem_DataType_New_Data_Object, implementation-data-type=uint8}
    DTS_DcmDspDid_FOR_DEM_SR_FF_57601_New_Data_Object: data-type-map=implementation-data-type=uint8
    DTS_DcmDspDid_FOR_DEM_SR_EDR_Record_ExtendedDataRecord0x01_Fault_occurrence_counter: data-type-map{application-data-type=Dem_DataType_Fault_occurrence_counter, implementation-data-type=uint8}
    DTS_DcmDspDid_FOR_DEM_SR_EDR_Record_ExtendedDataRecord0x01_Fault_pending_counter: data-type-map{application-data-type=Dem_DataType_Fault_pending_counter, implementation-data-type=uint8}
    DTS_DcmDspDid_FOR_DEM_SR_EDR_Record_ExtendedDataRecord0x01_Aged_counter: data-type-map{application-data-type=Dem_DataType_Aged_counter, implementation-data-type=uint8}
    DTS_DcmDspDid_FOR_DEM_SR_EDR_Record_ExtendedDataRecord0x01_Ageing_counter: data-type-map{application-data-type=Dem_DataType_Ageing_counter, implementation-data-type=uint8}
    DTS_DcmDspDid_DID_0x0100_New_Data_Object: data-type-map{application-data-type=Dcm_ArrDataType_0x100_New_Data_Object, implementation-data-type=Dcm_DataArrayTypeUint8_DID_0x0100_New_Data_ObjectType}
    DTS_DcmDspDid_DID_0x010B_Year: data-type-map{application-data-type=Dcm_DataType_0x10B_Year, implementation-data-type=uint8}
    DTS_DcmDspDid_DID_0x010B_Month: data-type-map{application-data-type=Dcm_DataType_0x10B_Month, implementation-data-type=uint8}
    DTS_DcmDspDid_DID_0x010B_Day: data-type-map{application-data-type=Dcm_DataType_0x10B_Day, implementation-data-type=uint8}
    DTS_DcmDspDid_DID_0x010B_Hour: data-type-map{application-data-type=Dcm_DataType_0x10B_Hour, implementation-data-type=uint8}
    DTS_DcmDspDid_DID_0x010B_Minute: data-type-map{application-data-type=Dcm_DataType_0x10B_Minute, implementation-data-type=uint8}
    DTS_DcmDspDid_DID_0x010B_Second: data-type-map{application-data-type=Dcm_DataType_0x10B_Second, implementation-data-type=uint8}
    DTS_DcmDspDid_DID_0x0112_New_Data_Object: data-type-map{application-data-type=Dcm_DataType_0x112_New_Data_Object, implementation-data-type=uint8}
    DTS_DcmDspDid_DID_0xB950_New_Data_Object: data-type-map{application-data-type=Dcm_ArrDataType_0xB950_New_Data_Object, implementation-data-type=Dcm_DataArrayTypeUint8_DID_0xB950_New_Data_ObjectType}
    DTS_DcmDspDid_DID_0xD001_New_Data_Object: data-type-map{application-data-type=Dcm_DataType_0xD001_New_Data_Object, implementation-data-type=uint8}
    DTS_DcmDspDid_DID_0xD901_New_Data_Object: data-type-map{application-data-type=Dcm_DataType_0xD901_New_Data_Object, implementation-data-type=uint8}
    DTS_DcmDspDid_DID_0xE101_New_Data_Object: data-type-map{application-data-type=Dcm_ArrDataType_0xE101_New_Data_Object, implementation-data-type=Dcm_DataArrayTypeUint8_DID_0xE101_New_Data_ObjectType}
    DTS_DcmDspDid_DID_0xE900_New_Data_Object: data-type-map{application-data-type=Dcm_DataType_0xE900_New_Data_Object, implementation-data-type=uint8}
    DTS_DcmDspDid_DID_0xF100_New_Data_Object: data-type-map{application-data-type=Dcm_ArrDataType_0xF100_New_Data_Object, implementation-data-type=Dcm_DataArrayTypeUint8_DID_0xF100_New_Data_ObjectType}
    DTS_DcmDspDid_DID_0xF100_New_Data_Object_1: data-type-map{application-data-type=Dcm_ArrDataType_0xF100_New_Data_Object_1, implementation-data-type=Dcm_DataArrayTypeUint8_DID_0xF100_New_Data_Object_1Type}
    DTS_DcmDspDid_DID_0xF{110..119}_New_Data_Object: data-type-map{application-data-type=Dcm_ArrDataType_0xF{110..119}_New_Data_Object, implementation-data-type=Dcm_DataArrayTypeUint8_DID_0xF{110..119}_New_Data_ObjectType}
    DTS_DcmDspDid_DID_0xF11A_New_Data_Object: data-type-map{application-data-type=Dcm_ArrDataType_0xF11A_New_Data_Object, implementation-data-type=Dcm_DataArrayTypeUint8_DID_0xF11A_New_Data_ObjectType}
    DTS_DcmDspDid_DID_0xF11B_New_Data_Object: data-type-map{application-data-type=Dcm_ArrDataType_0xF11B_New_Data_Object, implementation-data-type=Dcm_DataArrayTypeUint8_DID_0xF11B_New_Data_ObjectType}
    DTS_DcmDspDid_DID_0xF11C_New_Data_Object: data-type-map{application-data-type=Dcm_ArrDataType_0xF11C_New_Data_Object, implementation-data-type=Dcm_DataArrayTypeUint8_DID_0xF11C_New_Data_ObjectType}
    DTS_DcmDspDid_DID_0xF11D_New_Data_Object: data-type-map{application-data-type=Dcm_ArrDataType_0xF11D_New_Data_Object, implementation-data-type=Dcm_DataArrayTypeUint8_DID_0xF11D_New_Data_ObjectType}
    DTS_DcmDspDid_DID_0xF11E_New_Data_Object: data-type-map{application-data-type=Dcm_ArrDataType_0xF11E_New_Data_Object, implementation-data-type=Dcm_DataArrayTypeUint8_DID_0xF11E_New_Data_ObjectType}
    DTS_DcmDspDid_DID_0xF11F_New_Data_Object: data-type-map{application-data-type=Dcm_ArrDataType_0xF11F_New_Data_Object, implementation-data-type=Dcm_DataArrayTypeUint8_DID_0xF11F_New_Data_ObjectType}
    DTS_DcmDspDid_DID_0xF120_New_Data_Object: data-type-map{application-data-type=Dcm_ArrDataType_0xF120_New_Data_Object, implementation-data-type=Dcm_DataArrayTypeUint8_DID_0xF120_New_Data_ObjectType}
    DTS_DcmDspDid_DID_0xF121_New_Data_Object: data-type-map{application-data-type=Dcm_ArrDataType_0xF121_New_Data_Object, implementation-data-type=Dcm_DataArrayTypeUint8_DID_0xF121_New_Data_ObjectType}
    DTS_DcmDspDid_DID_0xF122_New_Data_Object: data-type-map{application-data-type=Dcm_ArrDataType_0xF183_New_Data_Object, implementation-data-type=Dcm_DataArrayTypeUint8_DID_0xF122_New_Data_ObjectType}
    DTS_DcmDspDid_DID_0xF122_New_Data_Object_2: data-type-map{application-data-type=Dcm_ArrDataType_0xF183_New_Data_Object_2, implementation-data-type=Dcm_DataArrayTypeUint8_DID_0xF122_New_Data_Object_2Type}
    DTS_DcmDspDid_DID_0xF187_New_Data_Object: data-type-map{application-data-type=Dcm_ArrDataType_0xF187_New_Data_Object, implementation-data-type=Dcm_DataArrayTypeUint8_DID_0xF187_New_Data_ObjectType}
    DTS_DcmDspDid_DID_0xF18A_New_Data_Object: data-type-map{application-data-type=Dcm_ArrDataType_0xF18A_New_Data_Object, implementation-data-type=Dcm_DataArrayTypeUint8_DID_0xF18A_New_Data_ObjectType}
    DTS_DcmDspDid_DID_0xF18B_New_Data_Object: data-type-map{application-data-type=Dcm_ArrDataType_0xF18B_New_Data_Object, implementation-data-type=Dcm_DataArrayTypeUint8_DID_0xF18B_New_Data_ObjectType}
    DTS_DcmDspDid_DID_0xF18C_New_Data_Object: data-type-map{application-data-type=Dcm_ArrDataType_0xF18C_New_Data_Object, implementation-data-type=Dcm_DataArrayTypeUint8_DID_0xF18C_New_Data_ObjectType}
    DTS_DcmDspDid_DID_0xF190_New_Data_Object: data-type-map{application-data-type=Dcm_ArrDataType_0xF190_New_Data_Object, implementation-data-type=Dcm_DataArrayTypeUint8_DID_0xF190_New_Data_ObjectType}
    DTS_DcmDspDid_DID_0xF192_New_Data_Object: data-type-map{application-data-type=Dcm_ArrDataType_0xF192_New_Data_Object, implementation-data-type=Dcm_DataArrayTypeUint8_DID_0xF192_New_Data_ObjectType}
    DTS_DcmDspDid_DID_0xF192_New_Data_Object_3: data-type-map{application-data-type=Dcm_ArrDataType_0xF192_New_Data_Object_3, implementation-data-type=Dcm_DataArrayTypeUint8_DID_0xF192_New_Data_Object_3Type}
    DTS_DcmDspDid_DID_0xF194_New_Data_Object: data-type-map{application-data-type=Dcm_ArrDataType_0xF194_New_Data_Object, implementation-data-type=Dcm_DataArrayTypeUint8_DID_0xF194_New_Data_ObjectType}
    DTS_DcmDspDid_DID_0xF194_New_Data_Object_4: data-type-map{application-data-type=Dcm_ArrDataType_0xF194_New_Data_Object_4, implementation-data-type=Dcm_DataArrayTypeUint8_DID_0xF194_New_Data_Object_4Type}
    DTS_DcmDspDid_DID_0xF198_New_Data_Object: data-type-map{application-data-type=Dcm_ArrDataType_0xF198_New_Data_Object, implementation-data-type=Dcm_DataArrayTypeUint8_DID_0xF198_New_Data_ObjectType}
    DTS_DcmDspDid_DID_0xF198_New_Data_Object_5: data-type-map{application-data-type=Dcm_ArrDataType_0xF198_New_Data_Object_5, implementation-data-type=Dcm_DataArrayTypeUint8_DID_0xF198_New_Data_Object_5Type}
    DTS_DcmDspDid_DID_0xF1A{0..2}_New_Data_Object: data-type-map{application-data-type=Dcm_ArrDataType_0xF1A{0..2}_New_Data_Object, implementation-data-type=Dcm_DataArrayTypeUint8_DID_0xF1A{0..2}_New_Data_ObjectType}
    DTS_DcmDspDid_DID_0xF1A5_New_Data_Object: data-type-map{application-data-type=Dcm_ArrDataType_0xF1A5_New_Data_Object, implementation-data-type=Dcm_DataArrayTypeUint8_DID_0xF1A5_New_Data_ObjectType}
    DTS_DcmDspDid_DID_0xF1A8_New_Data_Object: data-type-map{application-data-type=Dcm_ArrDataType_0xF1A8_New_Data_Object, implementation-data-type=Dcm_DataArrayTypeUint8_DID_0xF1A8_New_Data_ObjectType}
    DTS_DcmDspDid_DID_0xF1A9_New_Data_Object: data-type-map{application-data-type=Dcm_ArrDataType_0xF1A9_New_Data_Object, implementation-data-type=Dcm_DataArrayTypeUint8_DID_0xF1A9_New_Data_ObjectType}
    DTS_DcmDspDid_DID_0xF1AA_New_Data_Object: data-type-map{application-data-type=Dcm_ArrDataType_0xF1AA_New_Data_Object, implementation-data-type=Dcm_DataArrayTypeUint8_DID_0xF1AA_New_Data_ObjectType}
    DTS_DcmDiagnosticSessionControl: mode-request-type-map{implementation-data-type=uint8, mode-group=DcmDiagnosticSessionControl}
    DTS_DcmEcuReset: mode-request-type-map{implementation-data-type=uint8, mode-group=DcmEcuReset}
    DTS_DcmControlDTCSetting: mode-request-type-map{implementation-data-type=uint8, mode-group=DcmControlDTCSetting}
    DTS_DcmCommunicationControl_Can_Network_ETAS_Channel_Can_Network_ETAS: mode-request-type-map{implementation-data-type=uint8, mode-group=DcmCommunicationControl_Can_Network_ETAS_Channel_Can_Network_ETAS}
package /AUTOSAR_Dcm/SwcBswMappings
  swc bsw mapping SwcBswMappings: bsw-behavior=BswInternalBehavior, swc-bsw-runnable-mapping{bsw-entity=BSWSE_DcmMainFunction, swc-runnable=Dcm_MainFunction}, swc-behavior=IntBeh_Dcm
    synchronized-mode-groups:
      bsw-mode-group=DcmDiagnosticSessionControl, swc-mode-group=Pp_DcmDiagnosticSessionControl.MDGP_DcmDiagnosticSessionControl
      bsw-mode-group=DcmEcuReset, swc-mode-group=Pp_DcmEcuReset.MDGP_DcmEcuReset
      bsw-mode-group=DcmControlDTCSetting, swc-mode-group=Pp_DcmControlDTCSetting.MDGP_DcmControlDTCSetting
      bsw-mode-group=DcmCommunicationControl_Can_Network_ETAS_Channel_Can_Network_ETAS, swc-mode-group=Pp_DcmCommunicationControl_Can_Network_ETAS_Channel_Can_Network_ETAS.MDGP_DcmCommunicationControl_Can_Network_ETAS_Channel_Can_Network_ETAS
package /AUTOSAR_Dcm/PortInterfaces
  56 x sender receiver interface:
    DataServices_DID_0x0100_New_Data_Object
      data Data: type=Dcm_ArrDataType_0x100_New_Data_Object
    DataServices_DID_0x010B_Year
      data Data: type=Dcm_DataType_0x10B_Year
    DataServices_DID_0x010B_Month
      data Data: type=Dcm_DataType_0x10B_Month
    DataServices_DID_0x010B_Day
      data Data: type=Dcm_DataType_0x10B_Day
    DataServices_DID_0x010B_Hour
      data Data: type=Dcm_DataType_0x10B_Hour
    DataServices_DID_0x010B_Minute
      data Data: type=Dcm_DataType_0x10B_Minute
    DataServices_DID_0x010B_Second
      data Data: type=Dcm_DataType_0x10B_Second
    DataServices_DID_0x0112_New_Data_Object
      data Data: type=Dcm_DataType_0x112_New_Data_Object
    DataServices_DID_0xB950_New_Data_Object
      data Data: type=Dcm_ArrDataType_0xB950_New_Data_Object
    DataServices_DID_0xD001_New_Data_Object
      data Data: type=Dcm_DataType_0xD001_New_Data_Object
    DataServices_DID_0xD901_New_Data_Object
      data Data: type=Dcm_DataType_0xD901_New_Data_Object
    IOControlRequest_DID_0xD901_New_Data_Object: is-service=true
      data IOControlRequest_DID_0xD901_New_Data_Object: type=Dcm_IOControlRequest_DID_0xD901_New_Data_ObjectType
    DataServices_DID_0xE101_New_Data_Object
      data Data: type=Dcm_ArrDataType_0xE101_New_Data_Object
    DataServices_DID_0xE900_New_Data_Object
      data Data: type=Dcm_DataType_0xE900_New_Data_Object
    IOControlRequest_DID_0xE900_New_Data_Object: is-service=true
      data IOControlRequest_DID_0xE900_New_Data_Object: type=Dcm_IOControlRequest_DID_0xE900_New_Data_ObjectType
    DataServices_DID_0xF100_New_Data_Object
      data Data: type=Dcm_ArrDataType_0xF100_New_Data_Object
    DataServices_DID_0xF100_New_Data_Object_1
      data Data: type=Dcm_ArrDataType_0xF100_New_Data_Object_1
    DataServices_DID_0xF110_New_Data_Object
      data Data: type=Dcm_ArrDataType_0xF110_New_Data_Object
    DataServices_DID_0xF111_New_Data_Object
      data Data: type=Dcm_ArrDataType_0xF111_New_Data_Object
    DataServices_DID_0xF112_New_Data_Object
      data Data: type=Dcm_ArrDataType_0xF112_New_Data_Object
    DataServices_DID_0xF113_New_Data_Object
      data Data: type=Dcm_ArrDataType_0xF113_New_Data_Object
    DataServices_DID_0xF114_New_Data_Object
      data Data: type=Dcm_ArrDataType_0xF114_New_Data_Object
    DataServices_DID_0xF115_New_Data_Object
      data Data: type=Dcm_ArrDataType_0xF115_New_Data_Object
    DataServices_DID_0xF116_New_Data_Object
      data Data: type=Dcm_ArrDataType_0xF116_New_Data_Object
    DataServices_DID_0xF117_New_Data_Object
      data Data: type=Dcm_ArrDataType_0xF117_New_Data_Object
    DataServices_DID_0xF118_New_Data_Object
      data Data: type=Dcm_ArrDataType_0xF118_New_Data_Object
    DataServices_DID_0xF119_New_Data_Object
      data Data: type=Dcm_ArrDataType_0xF119_New_Data_Object
    DataServices_DID_0xF11A_New_Data_Object
      data Data: type=Dcm_ArrDataType_0xF11A_New_Data_Object
    DataServices_DID_0xF11B_New_Data_Object
      data Data: type=Dcm_ArrDataType_0xF11B_New_Data_Object
    DataServices_DID_0xF11C_New_Data_Object
      data Data: type=Dcm_ArrDataType_0xF11C_New_Data_Object
    DataServices_DID_0xF11D_New_Data_Object
      data Data: type=Dcm_ArrDataType_0xF11D_New_Data_Object
    DataServices_DID_0xF11E_New_Data_Object
      data Data: type=Dcm_ArrDataType_0xF11E_New_Data_Object
    DataServices_DID_0xF11F_New_Data_Object
      data Data: type=Dcm_ArrDataType_0xF11F_New_Data_Object
    DataServices_DID_0xF120_New_Data_Object
      data Data: type=Dcm_ArrDataType_0xF120_New_Data_Object
    DataServices_DID_0xF121_New_Data_Object
      data Data: type=Dcm_ArrDataType_0xF121_New_Data_Object
    DataServices_DID_0xF122_New_Data_Object
      data Data: type=Dcm_ArrDataType_0xF183_New_Data_Object
    DataServices_DID_0xF122_New_Data_Object_2
      data Data: type=Dcm_ArrDataType_0xF183_New_Data_Object_2
    DataServices_DID_0xF187_New_Data_Object
      data Data: type=Dcm_ArrDataType_0xF187_New_Data_Object
    DataServices_DID_0xF18A_New_Data_Object
      data Data: type=Dcm_ArrDataType_0xF18A_New_Data_Object
    DataServices_DID_0xF18B_New_Data_Object
      data Data: type=Dcm_ArrDataType_0xF18B_New_Data_Object
    DataServices_DID_0xF18C_New_Data_Object
      data Data: type=Dcm_ArrDataType_0xF18C_New_Data_Object
    DataServices_DID_0xF190_New_Data_Object
      data Data: type=Dcm_ArrDataType_0xF190_New_Data_Object
    DataServices_DID_0xF192_New_Data_Object
      data Data: type=Dcm_ArrDataType_0xF192_New_Data_Object
    DataServices_DID_0xF192_New_Data_Object_3
      data Data: type=Dcm_ArrDataType_0xF192_New_Data_Object_3
    DataServices_DID_0xF194_New_Data_Object
      data Data: type=Dcm_ArrDataType_0xF194_New_Data_Object
    DataServices_DID_0xF194_New_Data_Object_4
      data Data: type=Dcm_ArrDataType_0xF194_New_Data_Object_4
    DataServices_DID_0xF198_New_Data_Object
      data Data: type=Dcm_ArrDataType_0xF198_New_Data_Object
    DataServices_DID_0xF198_New_Data_Object_5
      data Data: type=Dcm_ArrDataType_0xF198_New_Data_Object_5
    DataServices_DID_0xF1A0_New_Data_Object
      data Data: type=Dcm_ArrDataType_0xF1A0_New_Data_Object
    DataServices_DID_0xF1A1_New_Data_Object
      data Data: type=Dcm_ArrDataType_0xF1A1_New_Data_Object
    DataServices_DID_0xF1A2_New_Data_Object
      data Data: type=Dcm_ArrDataType_0xF1A2_New_Data_Object
    DataServices_DID_0xF1A5_New_Data_Object
      data Data: type=Dcm_ArrDataType_0xF1A5_New_Data_Object
    DataServices_DID_0xF1A8_New_Data_Object
      data Data: type=Dcm_ArrDataType_0xF1A8_New_Data_Object
    DataServices_DID_0xF1A9_New_Data_Object
      data Data: type=Dcm_ArrDataType_0xF1A9_New_Data_Object
    DataServices_DID_0xF1AA_New_Data_Object
      data Data: type=Dcm_ArrDataType_0xF1AA_New_Data_Object
    IOControlResponse: is-service=true
      data IOOperationResponse: type=Dcm_IOOperationResponseType
  6 x client server interface, all with is-service=true:
    DCMServices
      5 x operation:
        GetActiveProtocol: possible-error=[DCMServices/E_OK, DCMServices/E_NOT_OK]
          arg ActiveProtocol: type=Dcm_ProtocolType, direction=OUT
        SetActiveDiagnostic: possible-error=DCMServices/E_OK
          arg active: type=boolean, direction=IN
        GetSesCtrlType: possible-error=[DCMServices/E_OK, DCMServices/E_NOT_OK]
          arg SesCtrlType: type=Dcm_SesCtrlType, direction=OUT
        GetSecurityLevel: possible-error=[DCMServices/E_OK, DCMServices/E_NOT_OK]
          arg SecLevel: type=Dcm_SecLevelType, direction=OUT
        ResetToDefaultSession: possible-error=[DCMServices/E_OK, DCMServices/E_NOT_OK]
      error E_OK: error-code=0
      error E_NOT_OK: error-code=1
    SecurityAccess_UnlockedL1
      operation GetSeed: possible-error=[SecurityAccess_UnlockedL1/E_OK, SecurityAccess_UnlockedL1/E_NOT_OK, SecurityAccess_UnlockedL1/DCM_E_PENDING]
        arg OpStatus: type=Dcm_OpStatusType, direction=IN
        arg Seed: type=Dcm_SeedArray_UnlockedL1Type, direction=OUT
        arg ErrorCode: type=Dcm_NegativeResponseCodeType, direction=OUT
      operation CompareKey: possible-error=[SecurityAccess_UnlockedL1/E_OK, SecurityAccess_UnlockedL1/E_NOT_OK, SecurityAccess_UnlockedL1/DCM_E_PENDING, SecurityAccess_UnlockedL1/DCM_E_COMPARE_KEY_FAILED]
        arg Key: type=Dcm_KeyArray_UnlockedL1Type, direction=IN
        arg OpStatus: type=Dcm_OpStatusType, direction=IN
        arg ErrorCode: type=Dcm_NegativeResponseCodeType, direction=OUT
      4 x error:
        E_OK: error-code=0
        E_NOT_OK: error-code=1
        DCM_E_PENDING: error-code=10
        DCM_E_COMPARE_KEY_FAILED: error-code=11
    SecurityAccess_Unlocked_L3
      operation GetSeed: possible-error=[SecurityAccess_Unlocked_L3/E_OK, SecurityAccess_Unlocked_L3/E_NOT_OK, SecurityAccess_Unlocked_L3/DCM_E_PENDING]
        arg OpStatus: type=Dcm_OpStatusType, direction=IN
        arg Seed: type=Dcm_SeedArray_Unlocked_L3Type, direction=OUT
        arg ErrorCode: type=Dcm_NegativeResponseCodeType, direction=OUT
      operation CompareKey: possible-error=[SecurityAccess_Unlocked_L3/E_OK, SecurityAccess_Unlocked_L3/E_NOT_OK, SecurityAccess_Unlocked_L3/DCM_E_PENDING, SecurityAccess_Unlocked_L3/DCM_E_COMPARE_KEY_FAILED]
        arg Key: type=Dcm_KeyArray_Unlocked_L3Type, direction=IN
        arg OpStatus: type=Dcm_OpStatusType, direction=IN
        arg ErrorCode: type=Dcm_NegativeResponseCodeType, direction=OUT
      4 x error:
        E_OK: error-code=0
        E_NOT_OK: error-code=1
        DCM_E_PENDING: error-code=10
        DCM_E_COMPARE_KEY_FAILED: error-code=11
    RoutineServices_Routine_Control_203
      operation Start: possible-error=[RoutineServices_Routine_Control_203/E_OK, RoutineServices_Routine_Control_203/E_NOT_OK, RoutineServices_Routine_Control_203/DCM_E_PENDING, RoutineServices_Routine_Control_203/DCM_E_FORCE_RCRRP]
        arg OpStatus: type=Dcm_OpStatusType, direction=IN
        arg DataOut_DcmDspStartRoutineOutSignal_0: type=Dcm_DataType_StartOut_515_Out_New_Data_Object, direction=OUT
        arg ErrorCode: type=Dcm_NegativeResponseCodeType, direction=OUT
      4 x error:
        E_OK: error-code=0
        E_NOT_OK: error-code=1
        DCM_E_PENDING: error-code=10
        DCM_E_FORCE_RCRRP: error-code=12
    RoutineServices_X_Routine_Control_ABFE
      operation Start: possible-error=[RoutineServices_X_Routine_Control_ABFE/E_OK, RoutineServices_X_Routine_Control_ABFE/E_NOT_OK, RoutineServices_X_Routine_Control_ABFE/DCM_E_PENDING, RoutineServices_X_Routine_Control_ABFE/DCM_E_FORCE_RCRRP]
        arg OpStatus: type=Dcm_OpStatusType, direction=IN
        arg ErrorCode: type=Dcm_NegativeResponseCodeType, direction=OUT
      4 x error:
        E_OK: error-code=0
        E_NOT_OK: error-code=1
        DCM_E_PENDING: error-code=10
        DCM_E_FORCE_RCRRP: error-code=12
    RoutineServices_Routine_Control_ABFF
      operation Start: possible-error=[RoutineServices_Routine_Control_ABFF/E_OK, RoutineServices_Routine_Control_ABFF/E_NOT_OK, RoutineServices_Routine_Control_ABFF/DCM_E_PENDING, RoutineServices_Routine_Control_ABFF/DCM_E_FORCE_RCRRP]
        arg OpStatus: type=Dcm_OpStatusType, direction=IN
        arg ErrorCode: type=Dcm_NegativeResponseCodeType, direction=OUT
      operation RequestResults: possible-error=[RoutineServices_Routine_Control_ABFF/E_OK, RoutineServices_Routine_Control_ABFF/E_NOT_OK, RoutineServices_Routine_Control_ABFF/DCM_E_PENDING, RoutineServices_Routine_Control_ABFF/DCM_E_FORCE_RCRRP]
        arg OpStatus: type=Dcm_OpStatusType, direction=IN
        arg DataOut_DcmDspRequestRoutineResultsOutSignal_0: type=Dcm_DataType_RequestOut_44031_Out_New_Data_Object, direction=OUT
        arg ErrorCode: type=Dcm_NegativeResponseCodeType, direction=OUT
      4 x error:
        E_OK: error-code=0
        E_NOT_OK: error-code=1
        DCM_E_PENDING: error-code=10
        DCM_E_FORCE_RCRRP: error-code=12
  4 x mode switch interface, all with is-service=true:
    DcmDiagnosticSessionControl
      mode group MDGP_DcmDiagnosticSessionControl: type=DcmDiagnosticSessionControl
    DcmEcuReset
      mode group MDGP_DcmEcuReset: type=DcmEcuReset
    DcmControlDTCSetting
      mode group MDGP_DcmControlDTCSetting: type=DcmControlDTCSetting
    DcmCommunicationControl_Can_Network_ETAS_Channel_Can_Network_ETAS
      mode group MDGP_DcmCommunicationControl_Can_Network_ETAS_Channel_Can_Network_ETAS: type=DcmCommunicationControl_Can_Network_ETAS_Channel_Can_Network_ETAS
